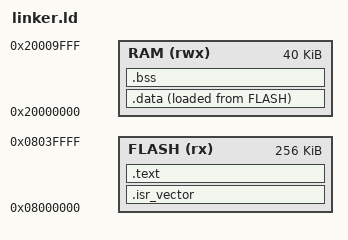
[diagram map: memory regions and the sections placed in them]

ENTRY(Reset_Handler)

MEMORY {
    FLASH (rx)  : ORIGIN = 0x08000000, LENGTH = 256K
    RAM   (rwx) : ORIGIN = 0x20000000, LENGTH = 40K
}

_estack = ORIGIN(RAM) + LENGTH(RAM);

SECTIONS {
    .isr_vector : {
        KEEP(*(.isr_vector))
    } > FLASH

    .text : {
        *(.text*)
        *(.rodata*)
    } > FLASH

    .data : {
        *(.data*)
    } > RAM AT > FLASH

    .bss (NOLOAD) : {
        *(.bss*)
        *(COMMON)
    } > RAM
}
